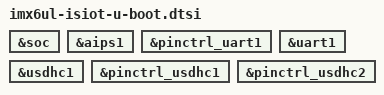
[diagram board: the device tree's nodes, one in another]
// SPDX-License-Identifier: GPL-2.0+
/*
 * Copyright (C) 2018 Jagan Teki <jagan@amarulasolutions.com>
 */

#include "imx6ul-u-boot.dtsi"

&soc {
	bootph-all;
};

&aips1 {
	bootph-all;
};

&pinctrl_uart1 {
	bootph-all;
};

&uart1 {
	bootph-all;
};

&usdhc1 {
	bootph-pre-ram;
};

&pinctrl_usdhc1 {
	bootph-pre-ram;
};

&pinctrl_usdhc2 {
	bootph-pre-ram;
};
